AUTOSAR XML (schema 00050)
package /FCADT/ComponentTypes
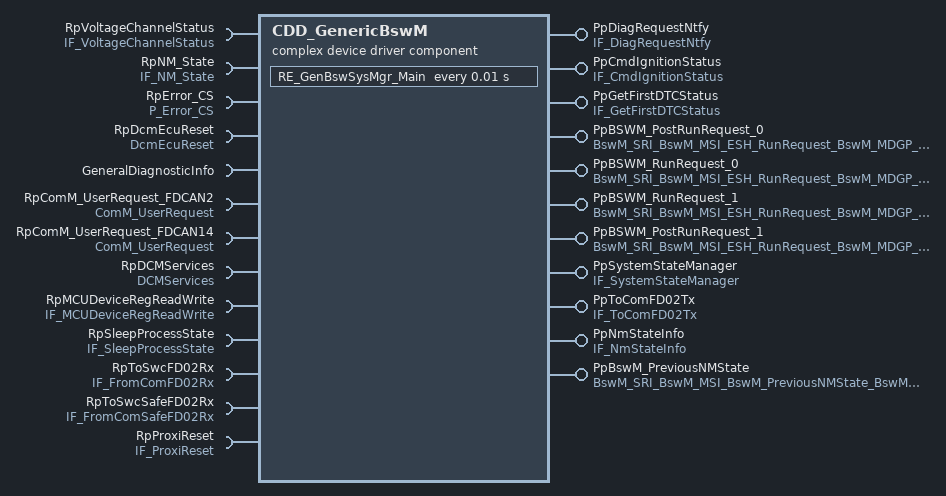
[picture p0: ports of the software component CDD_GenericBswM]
  complex device driver sw component type CDD_GenericBswM
    require port RpVoltageChannelStatus: nonqueued-receiver-com-spec{data-element=BatteryVoltageStatus, init-value=constant-reference=init_BatteryVoltageStatus}, required-interface=IF_VoltageChannelStatus
    provide port PpDiagRequestNtfy: mode-switch-sender-com-spec{mode-group=SYSModeRequestType, queue-length=1}, provided-interface=IF_DiagRequestNtfy
    require port RpNM_State: mode-switch-receiver-com-spec=Mode, required-interface=IF_NM_State
    provide port PpCmdIgnitionStatus: mode-switch-sender-com-spec{mode-group=Current_CmdIgnition, queue-length=1}, provided-interface=IF_CmdIgnitionStatus
    provide port PpGetFirstDTCStatus: nonqueued-sender-com-spec{data-element=DeFirstDTCStatus, init-value=0}, provided-interface=IF_GetFirstDTCStatus
    require port RpError_CS: client-com-spec=ReportErrorStatus1_0_QM, required-interface=P_Error_CS
    require port RpDcmEcuReset: mode-switch-receiver-com-spec=DcmEcuReset, required-interface=DcmEcuReset
    provide port PpBSWM_PostRunRequest_0: nonqueued-sender-com-spec=requestedMode, provided-interface=BswM_SRI_BswM_MSI_ESH_RunRequest_BswM_MDGP_ESH_RunRequest
    provide port PpBSWM_RunRequest_0: nonqueued-sender-com-spec=requestedMode, provided-interface=BswM_SRI_BswM_MSI_ESH_RunRequest_BswM_MDGP_ESH_RunRequest
    provide port PpBSWM_RunRequest_1: nonqueued-sender-com-spec=requestedMode, provided-interface=BswM_SRI_BswM_MSI_ESH_RunRequest_BswM_MDGP_ESH_RunRequest
    require port GeneralDiagnosticInfo: required-interface=GeneralDiagnosticInfo
      required-com-specs:
        GetMonitorStatus
        GetDebouncingOfEvent
        GetEventEnableCondition
        GetEventExtendedDataRecordEx
        GetEventFreezeFrameDataEx
        GetFaultDetectionCounter
        GetDTCOfEvent
        GetEventTested
        GetEventFailed
        GetEventStatus
        GetEventUdsStatus
    provide port PpBSWM_PostRunRequest_1: nonqueued-sender-com-spec=requestedMode, provided-interface=BswM_SRI_BswM_MSI_ESH_RunRequest_BswM_MDGP_ESH_RunRequest
    require port RpComM_UserRequest_FDCAN2: required-com-specs=[GetRequestedComMode, GetMaxComMode, GetCurrentComMode, RequestComMode], required-interface=ComM_UserRequest
    require port RpComM_UserRequest_FDCAN14: required-com-specs=[GetRequestedComMode, GetMaxComMode, GetCurrentComMode, RequestComMode], required-interface=ComM_UserRequest
    provide port PpSystemStateManager: nonqueued-sender-com-spec=SysM_State, provided-interface=IF_SystemStateManager
    5 x require port:
      RpDCMServices: required-interface=DCMServices
        required-com-specs:
          GetRequestKind
          SetActiveDiagnostic
          GetSecurityLevel
          ResetToDefaultSession
          GetSesCtrlType
          GetActiveProtocol
      RpMCUDeviceRegReadWrite: required-com-specs=[MCUWriteDeviceReg, MCUReadDeviceRegData, MCUReadDeviceReg], required-interface=IF_MCUDeviceRegReadWrite
      RpSleepProcessState: nonqueued-receiver-com-spec{data-element=status, filter=data-filter-type=ALWAYS, init-value=0}, required-interface=IF_SleepProcessState
      RpToSwcFD02Rx: required-interface=IF_FromComFD02Rx
        required-com-specs:
          data-element=Altitude_RMSE_C2, filter=data-filter-type=ALWAYS, init-value=255
          data-element=Battery_Volt_1, filter=data-filter-type=ALWAYS, init-value=0
          data-element=BSM_THA_Brk_Resp, filter=data-filter-type=ALWAYS, init-value=0
          data-element=CurrentCanNMState_FD01_BCM, filter=data-filter-type=ALWAYS, init-value=0
          data-element=CurrentCanNMState_FD01_SGW, filter=data-filter-type=ALWAYS, init-value=0
          data-element=CurrentCanNMState_FD02_BCM, filter=data-filter-type=ALWAYS, init-value=0
          data-element=CurrentCanNMState_FD02_BSM2, filter=data-filter-type=ALWAYS, init-value=0
          data-element=CurrentCanNMState_FD02_CADM2, filter=data-filter-type=ALWAYS, init-value=0
          data-element=CurrentCanNMState_FD02_EPS, filter=data-filter-type=ALWAYS, init-value=0
          data-element=CurrentCanNMState_FD02_ORC, filter=data-filter-type=ALWAYS, init-value=0
          data-element=CurrentCanNMState_FD02_SGW, filter=data-filter-type=ALWAYS, init-value=0
          data-element=CurrentCanNMState_FD02_TRLR_REV, filter=data-filter-type=ALWAYS, init-value=0
          data-element=CurrentCanNMState_FD03_BCM, filter=data-filter-type=ALWAYS, init-value=0
          data-element=CurrentCanNMState_FD03_SGW, filter=data-filter-type=ALWAYS, init-value=0
          data-element=CurrentCanNMState_FD04_BCM, filter=data-filter-type=ALWAYS, init-value=0
          data-element=CurrentCanNMState_FD08_SGW, filter=data-filter-type=ALWAYS, init-value=0
          data-element=CurrentCanNMState_FD11_SGW, filter=data-filter-type=ALWAYS, init-value=0
          data-element=CurrentFailSts_FD01_BCM, filter=data-filter-type=ALWAYS, init-value=0
          data-element=CurrentFailSts_FD01_SGW, filter=data-filter-type=ALWAYS, init-value=0
          data-element=CurrentFailSts_FD02_BCM, filter=data-filter-type=ALWAYS, init-value=0
          data-element=CurrentFailSts_FD02_BSM2, filter=data-filter-type=ALWAYS, init-value=0
          data-element=CurrentFailSts_FD02_CADM2, filter=data-filter-type=ALWAYS, init-value=0
          data-element=CurrentFailSts_FD02_EPS, filter=data-filter-type=ALWAYS, init-value=0
          data-element=CurrentFailSts_FD02_ORC, filter=data-filter-type=ALWAYS, init-value=0
          data-element=CurrentFailSts_FD02_SGW, filter=data-filter-type=ALWAYS, init-value=0
          data-element=CurrentFailSts_FD02_TRLR_REV, filter=data-filter-type=ALWAYS, init-value=0
          data-element=CurrentFailSts_FD03_BCM, filter=data-filter-type=ALWAYS, init-value=0
          data-element=CurrentFailSts_FD03_SGW, filter=data-filter-type=ALWAYS, init-value=0
          data-element=CurrentFailSts_FD04_BCM, filter=data-filter-type=ALWAYS, init-value=0
          data-element=CurrentFailSts_FD08_SGW, filter=data-filter-type=ALWAYS, init-value=0
          data-element=CurrentFailSts_FD11_SGW, filter=data-filter-type=ALWAYS, init-value=0
          data-element=DeltaTimestamp_IMUdata, filter=data-filter-type=ALWAYS, init-value=255
          data-element=DES_FD01_BCM, filter=data-filter-type=ALWAYS, init-value=0
          data-element=DES_FD01_SGW, filter=data-filter-type=ALWAYS, init-value=0
          data-element=DES_FD02_BCM, filter=data-filter-type=ALWAYS, init-value=0
          data-element=DES_FD02_BSM2, filter=data-filter-type=ALWAYS, init-value=0
          data-element=DES_FD02_CADM2, filter=data-filter-type=ALWAYS, init-value=0
          data-element=DES_FD02_EPS, filter=data-filter-type=ALWAYS, init-value=0
          data-element=DES_FD02_ORC, filter=data-filter-type=ALWAYS, init-value=0
          data-element=DES_FD02_SGW, filter=data-filter-type=ALWAYS, init-value=0
          data-element=DES_FD02_TRLR_REV, filter=data-filter-type=ALWAYS, init-value=0
          data-element=DES_FD03_BCM, filter=data-filter-type=ALWAYS, init-value=0
          data-element=DES_FD03_SGW, filter=data-filter-type=ALWAYS, init-value=0
          data-element=DES_FD04_BCM, filter=data-filter-type=ALWAYS, init-value=0
          data-element=DES_FD08_SGW, filter=data-filter-type=ALWAYS, init-value=0
          data-element=DES_FD11_SGW, filter=data-filter-type=ALWAYS, init-value=0
          data-element=Digit_{01..11}, filter=data-filter-type=ALWAYS, init-value=0
          data-element=EOL_FD01_BCM, filter=data-filter-type=ALWAYS, init-value=0
          data-element=EOL_FD01_SGW, filter=data-filter-type=ALWAYS, init-value=0
          data-element=EOL_FD02_BCM, filter=data-filter-type=ALWAYS, init-value=0
          data-element=EOL_FD02_BSM2, filter=data-filter-type=ALWAYS, init-value=0
          data-element=EOL_FD02_CADM2, filter=data-filter-type=ALWAYS, init-value=0
          data-element=EOL_FD02_EPS, filter=data-filter-type=ALWAYS, init-value=0
          data-element=EOL_FD02_ORC, filter=data-filter-type=ALWAYS, init-value=0
          data-element=EOL_FD02_SGW, filter=data-filter-type=ALWAYS, init-value=0
          data-element=EOL_FD02_TRLR_REV, filter=data-filter-type=ALWAYS, init-value=0
          data-element=EOL_FD03_BCM, filter=data-filter-type=ALWAYS, init-value=0
          data-element=EOL_FD03_SGW, filter=data-filter-type=ALWAYS, init-value=0
          data-element=EOL_FD04_BCM, filter=data-filter-type=ALWAYS, init-value=0
          data-element=EOL_FD08_SGW, filter=data-filter-type=ALWAYS, init-value=0
          data-element=EOL_FD11_SGW, filter=data-filter-type=ALWAYS, init-value=0
          data-element=EPBSts, filter=data-filter-type=ALWAYS, init-value=0
          data-element=GenericFailSts_FD01_BCM, filter=data-filter-type=ALWAYS, init-value=0
          data-element=GenericFailSts_FD01_SGW, filter=data-filter-type=ALWAYS, init-value=0
          data-element=GenericFailSts_FD02_BCM, filter=data-filter-type=ALWAYS, init-value=0
          data-element=GenericFailSts_FD02_BSM2, filter=data-filter-type=ALWAYS, init-value=0
          data-element=GenericFailSts_FD02_CADM2, filter=data-filter-type=ALWAYS, init-value=0
          data-element=GenericFailSts_FD02_EPS, filter=data-filter-type=ALWAYS, init-value=0
          data-element=GenericFailSts_FD02_ORC, filter=data-filter-type=ALWAYS, init-value=0
          data-element=GenericFailSts_FD02_SGW, filter=data-filter-type=ALWAYS, init-value=0
          data-element=GenericFailSts_FD02_TRLR_REV, filter=data-filter-type=ALWAYS, init-value=0
          data-element=GenericFailSts_FD03_BCM, filter=data-filter-type=ALWAYS, init-value=0
          data-element=GenericFailSts_FD03_SGW, filter=data-filter-type=ALWAYS, init-value=0
          data-element=GenericFailSts_FD04_BCM, filter=data-filter-type=ALWAYS, init-value=0
          data-element=GenericFailSts_FD08_SGW, filter=data-filter-type=ALWAYS, init-value=0
          data-element=GenericFailSts_FD11_SGW, filter=data-filter-type=ALWAYS, init-value=0
          data-element=Heading_Angle_C2, filter=data-filter-type=ALWAYS, init-value=65535
          data-element=IgnitionOnCounter, filter=data-filter-type=ALWAYS, init-value=0
          data-element=LatAcceleration_C2, filter=data-filter-type=ALWAYS, init-value=4095
          data-element=LatAccelerationOffset_BSM, filter=data-filter-type=ALWAYS, init-value=255
          data-element=Latitude_RMSE_C2, filter=data-filter-type=ALWAYS, init-value=255
          data-element=LHF_FastPulseCounter, filter=data-filter-type=ALWAYS, init-value=0
          data-element=LHF_Spin, filter=data-filter-type=ALWAYS, init-value=0
          data-element=LHFWheelSpeed, filter=data-filter-type=ALWAYS, init-value=0
          data-element=LHR_FastPulseCounter, filter=data-filter-type=ALWAYS, init-value=0
          data-element=LHR_Spin, filter=data-filter-type=ALWAYS, init-value=0
          data-element=LHRWheelSpeed, filter=data-filter-type=ALWAYS, init-value=0
          data-element=LongAcceleration_C2, filter=data-filter-type=ALWAYS, init-value=4095
          data-element=LongAccelerationOffset_BSM, filter=data-filter-type=ALWAYS, init-value=255
          data-element=Longitude_RMSE_C2, filter=data-filter-type=ALWAYS, init-value=255
          data-element=OperationalModeSts, filter=data-filter-type=ALWAYS, init-value=0
          data-element=Pitch_RMSE_C2, filter=data-filter-type=ALWAYS, init-value=255
          data-element=PitchRate_C2, filter=data-filter-type=ALWAYS, init-value=4095
          data-element=PreviousCanNMState_FD01_BCM, filter=data-filter-type=ALWAYS, init-value=0
          data-element=PreviousCanNMState_FD01_SGW, filter=data-filter-type=ALWAYS, init-value=0
          data-element=PreviousCanNMState_FD02_BCM, filter=data-filter-type=ALWAYS, init-value=0
          data-element=PreviousCanNMState_FD02_BSM2, filter=data-filter-type=ALWAYS, init-value=0
          data-element=PreviousCanNMState_FD02_CADM2, filter=data-filter-type=ALWAYS, init-value=0
          data-element=PreviousCanNMState_FD02_EPS, filter=data-filter-type=ALWAYS, init-value=0
          data-element=PreviousCanNMState_FD02_ORC, filter=data-filter-type=ALWAYS, init-value=0
          data-element=PreviousCanNMState_FD02_SGW, filter=data-filter-type=ALWAYS, init-value=0
          data-element=PreviousCanNMState_FD02_TRLR_REV, filter=data-filter-type=ALWAYS, init-value=0
          data-element=PreviousCanNMState_FD03_BCM, filter=data-filter-type=ALWAYS, init-value=0
          data-element=PreviousCanNMState_FD03_SGW, filter=data-filter-type=ALWAYS, init-value=0
          data-element=PreviousCanNMState_FD04_BCM, filter=data-filter-type=ALWAYS, init-value=0
          data-element=PreviousCanNMState_FD08_SGW, filter=data-filter-type=ALWAYS, init-value=0
          data-element=PreviousCanNMState_FD11_SGW, filter=data-filter-type=ALWAYS, init-value=0
          data-element=REF_VEH_SPEED, filter=data-filter-type=ALWAYS, init-value=1023
          data-element=RemStActvSts, filter=data-filter-type=ALWAYS, init-value=0
          data-element=RHF_FastPulseCounter, filter=data-filter-type=ALWAYS, init-value=0
          data-element=RHF_Spin, filter=data-filter-type=ALWAYS, init-value=0
          data-element=RHFWheelSpeed, filter=data-filter-type=ALWAYS, init-value=0
          data-element=RHR_FastPulseCounter, filter=data-filter-type=ALWAYS, init-value=0
          data-element=RHR_Spin, filter=data-filter-type=ALWAYS, init-value=0
          data-element=RHRWheelSpeed, filter=data-filter-type=ALWAYS, init-value=0
          data-element=Roll_RMSE_C2, filter=data-filter-type=ALWAYS, init-value=255
          data-element=RollRate_C2, filter=data-filter-type=ALWAYS, init-value=4095
          data-element=SBR1RowDriverSeatSts, filter=data-filter-type=ALWAYS, init-value=3
          data-element=StayActiveSource_FD01_BCM, filter=data-filter-type=ALWAYS, init-value=0
          data-element=StayActiveSource_FD01_SGW, filter=data-filter-type=ALWAYS, init-value=0
          data-element=StayActiveSource_FD02_BCM, filter=data-filter-type=ALWAYS, init-value=0
          data-element=StayActiveSource_FD02_BSM2, filter=data-filter-type=ALWAYS, init-value=0
          data-element=StayActiveSource_FD02_CADM2, filter=data-filter-type=ALWAYS, init-value=0
          data-element=StayActiveSource_FD02_EPS, filter=data-filter-type=ALWAYS, init-value=0
          data-element=StayActiveSource_FD02_ORC, filter=data-filter-type=ALWAYS, init-value=0
          data-element=StayActiveSource_FD02_SGW, filter=data-filter-type=ALWAYS, init-value=0
          data-element=StayActiveSource_FD02_TRLR_REV, filter=data-filter-type=ALWAYS, init-value=0
          data-element=StayActiveSource_FD03_BCM, filter=data-filter-type=ALWAYS, init-value=0
          data-element=StayActiveSource_FD03_SGW, filter=data-filter-type=ALWAYS, init-value=0
          data-element=StayActiveSource_FD04_BCM, filter=data-filter-type=ALWAYS, init-value=0
          data-element=StayActiveSource_FD08_SGW, filter=data-filter-type=ALWAYS, init-value=0
          data-element=StayActiveSource_FD11_SGW, filter=data-filter-type=ALWAYS, init-value=0
          data-element=TotalOdometer, filter=data-filter-type=ALWAYS, init-value=0
          data-element=TRSC_CenterBtn_Sts, filter=data-filter-type=ALWAYS, init-value=0
          data-element=TRSC_EnableBtn_Sts, filter=data-filter-type=ALWAYS, init-value=0
          data-element=TRSC_RawKnob, filter=data-filter-type=ALWAYS, init-value=0
          data-element=TurnIndicatorSts, filter=data-filter-type=ALWAYS, init-value=0
          data-element=VehicleStandStillSts, filter=data-filter-type=ALWAYS, init-value=1
          data-element=VerticalAcceleration_C2, filter=data-filter-type=ALWAYS, init-value=4095
          data-element=WakeupSource_FD01_ADCM, filter=data-filter-type=ALWAYS, init-value=0
          data-element=WakeupSource_FD01_BCM, filter=data-filter-type=ALWAYS, init-value=0
          data-element=WakeupSource_FD01_SGW, filter=data-filter-type=ALWAYS, init-value=0
          data-element=WakeupSource_FD02_BCM, filter=data-filter-type=ALWAYS, init-value=0
          data-element=WakeupSource_FD02_BSM2, filter=data-filter-type=ALWAYS, init-value=0
          data-element=WakeupSource_FD02_CADM2, filter=data-filter-type=ALWAYS, init-value=0
          data-element=WakeupSource_FD02_EPS, filter=data-filter-type=ALWAYS, init-value=0
          data-element=WakeupSource_FD02_ORC, filter=data-filter-type=ALWAYS, init-value=0
          data-element=WakeupSource_FD02_SGW, filter=data-filter-type=ALWAYS, init-value=0
          data-element=WakeupSource_FD02_TRLR_REV, filter=data-filter-type=ALWAYS, init-value=0
          data-element=WakeupSource_FD03_BCM, filter=data-filter-type=ALWAYS, init-value=0
          data-element=WakeupSource_FD03_SGW, filter=data-filter-type=ALWAYS, init-value=0
          data-element=WakeupSource_FD04_BCM, filter=data-filter-type=ALWAYS, init-value=0
          data-element=WakeupSource_FD08_SGW, filter=data-filter-type=ALWAYS, init-value=0
          data-element=WakeupSource_FD11_SGW, filter=data-filter-type=ALWAYS, init-value=0
          data-element=YawRate_C2, filter=data-filter-type=ALWAYS, init-value=4095
          data-element=YawRate_RMSE_C2, filter=data-filter-type=ALWAYS, init-value=255
      RpToSwcSafeFD02Rx: required-interface=IF_FromComSafeFD02Rx
        required-com-specs:
          data-element=Active_Park_Mode, filter=data-filter-type=ALWAYS, init-value=0
          data-element=Active_Park_Prox_Chime, filter=data-filter-type=ALWAYS, init-value=0
          data-element=APARequestSts, filter=data-filter-type=ALWAYS, init-value=0
          data-element=Backup_Cam_Delay, filter=data-filter-type=ALWAYS, init-value=0
          data-element=Brk_Stat, filter=data-filter-type=ALWAYS, init-value=0
          data-element=CmdIgnSts, filter=data-filter-type=ALWAYS, init-value=0
          data-element=DriverDoorSts, filter=data-filter-type=ALWAYS, init-value=0
          data-element=DynamicGrid, filter=data-filter-type=ALWAYS, init-value=1
          data-element=ExternalTemperature, filter=data-filter-type=ALWAYS, init-value=0
          data-element=FT_PAMRequestSts, filter=data-filter-type=ALWAYS, init-value=0
          data-element=Fwrd_Cam_Guidelines, filter=data-filter-type=ALWAYS, init-value=0
          data-element=GearEngaged, filter=data-filter-type=ALWAYS, init-value=0
          data-element=HAS_Status_C2, filter=data-filter-type=ALWAYS, init-value=0
          data-element=LanguageSelection, filter=data-filter-type=ALWAYS, init-value=0
          data-element=LatAcceleration_BSM, filter=data-filter-type=ALWAYS, init-value=4095
          data-element=LHRDoorSts, filter=data-filter-type=ALWAYS, init-value=0
          data-element=LongAcceleration_BSM, filter=data-filter-type=ALWAYS, init-value=4095
          data-element=LwsAngle, filter=data-filter-type=ALWAYS, init-value=0
          data-element=LwsAngleType, filter=data-filter-type=ALWAYS, init-value=0
          data-element=LwsSpeed, filter=data-filter-type=ALWAYS, init-value=0
          data-element=MRM_STATUS_C2, filter=data-filter-type=ALWAYS, init-value=0
          data-element=PamChimeVolumeFront, filter=data-filter-type=ALWAYS, init-value=1
          data-element=PamChimeVolumeRear, filter=data-filter-type=ALWAYS, init-value=1
          data-element=PAMRequestSts, filter=data-filter-type=ALWAYS, init-value=0
          data-element=PsngrDoorSts, filter=data-filter-type=ALWAYS, init-value=0
          data-element=Rear_Brk_Asst, filter=data-filter-type=ALWAYS, init-value=0
          data-element=RHatchSts, filter=data-filter-type=ALWAYS, init-value=0
          data-element=RHRDoorSts, filter=data-filter-type=ALWAYS, init-value=0
          data-element=ShiftLeverPosition, filter=data-filter-type=ALWAYS, init-value=0
          data-element=SVC_Guidelines, filter=data-filter-type=ALWAYS, init-value=0
          data-element=TargetGear, filter=data-filter-type=ALWAYS, init-value=15
          data-element=TCASERANGESTATUS, filter=data-filter-type=ALWAYS, init-value=0
          data-element=TGW_CAMERA_DISP_STAT, filter=data-filter-type=ALWAYS, init-value=0
          data-element=TrailerConnectionSts, filter=data-filter-type=ALWAYS, init-value=0
          data-element=TRANS_ADAS_Inhibit, filter=data-filter-type=ALWAYS, init-value=0
          data-element=TransmissionSailingSts, filter=data-filter-type=ALWAYS, init-value=0
          data-element=VehicleSpeedVSOSig, filter=data-filter-type=ALWAYS, init-value=0
          data-element=YawRate_BSM, filter=data-filter-type=ALWAYS, init-value=4095
          data-element=VIN_MSG, filter=data-filter-type=ALWAYS
          data-element=VIN_DATA, filter=data-filter-type=ALWAYS
          data-element=RR_Lvl_Adj, filter=data-filter-type=ALWAYS
          data-element=RR_Lvl, filter=data-filter-type=ALWAYS
          data-element=RL_Lvl_Adj, filter=data-filter-type=ALWAYS
          data-element=RL_Lvl, filter=data-filter-type=ALWAYS
          data-element=HU_TRSC_EnableBtn_Sts, filter=data-filter-type=ALWAYS
          data-element=GearEngagedForDisplay, filter=data-filter-type=ALWAYS
          data-element=FR_Lvl_Adj, filter=data-filter-type=ALWAYS
          data-element=FR_Lvl, filter=data-filter-type=ALWAYS
          data-element=FL_Lvl_Adj, filter=data-filter-type=ALWAYS
          data-element=FL_Lvl, filter=data-filter-type=ALWAYS
          data-element=ESS_ENG_ST_W, filter=data-filter-type=ALWAYS
          data-element=EngineSts_W, filter=data-filter-type=ALWAYS
          data-element=ECM_TRSC_Resp, filter=data-filter-type=ALWAYS
          data-element=ECM_THA_Resp, filter=data-filter-type=ALWAYS
          data-element=ASCM_SysFail, filter=data-filter-type=ALWAYS
          data-element=ASCM_Stat, filter=data-filter-type=ALWAYS
          data-element=PdlPosActual, filter=data-filter-type=ALWAYS
          data-element=THA_SteeringTouchStat, filter=data-filter-type=ALWAYS
          data-element=EPS_THA_SteeringTorqueResp, filter=data-filter-type=ALWAYS
          data-element=EPS_THA_DriverTorqueOverride, filter=data-filter-type=ALWAYS
          data-element=EPS_SteeringTouq_Resp, filter=data-filter-type=ALWAYS
          data-element=EPS_SteeringTouchStat, filter=data-filter-type=ALWAYS
          data-element=ShiftLeverPositionReq, filter=data-filter-type=ALWAYS
          data-element=Shifter_ADAS_Inhibit, filter=data-filter-type=ALWAYS
          data-element=ITBM_TrlrStat, filter=data-filter-type=ALWAYS
          data-element=CM_TCH_Y_COORD, filter=data-filter-type=ALWAYS
          data-element=CM_TCH_X_COORD, filter=data-filter-type=ALWAYS
          data-element=CM_TCH_STAT, filter=data-filter-type=ALWAYS
          data-element=CameraDisplaySts2, filter=data-filter-type=ALWAYS
    provide port PpToComFD02Tx: provided-interface=IF_ToComFD02Tx
      provided-com-specs:
        data-element=CurrentCanNMState_FD02_PAM, init-value=0
        data-element=CurrentFailSts_FD02_PAM, init-value=0
        data-element=DES_FD02_PAM, init-value=0
        data-element=Digit_{01..11}_PAM, init-value=0
        data-element=EOL_FD02_PAM, init-value=0
        data-element=GenericFailSts_FD02_PAM, init-value=0
        {data-element=N_PDU, init-value=[rule-based-values={rule=FILL_UNTIL_END, rule-arguments=0}]}
        data-element=PreviousCanNMState_FD02_PAM, init-value=0
        {data-element=StayActiveSource_FD02_PAM, init-value=[rule-based-values={rule=FILL_UNTIL_END, rule-arguments=0}]}
        data-element=THA_EPB_Req, init-value=0
        data-element=THA_Speed_Limit, init-value=0
        data-element=THA_SpeedLimit_Req, init-value=0
        data-element=THA_STAT, init-value=0
        data-element=THA_SteeringDamping, init-value=78.125
        data-element=THA_SteeringTorqueInfo, init-value=0
        data-element=THA_SteeringTorqueReq, init-value=0
        data-element=Trailer_Angle, init-value=0
        data-element=Trailer_Angle_Sign, init-value=0
        data-element=Trailer_Calibration, init-value=0
        data-element=TrlrHitchLight_Cntrl, init-value=0
        data-element=TRSC_PopupDisp_Info, init-value=0
        data-element=TRSC_SpeedLimit_Req, init-value=0
        data-element=TRSC_STAT, init-value=1
        data-element=TRSC_SteeringDamping, init-value=100
        data-element=TRSC_SteeringTorqueInfo, init-value=0
        data-element=TRSC_SteeringTorqueReq, init-value=0
        data-element=TRSC_VehicleStop_Req, init-value=3
        data-element=TRSCMoreCamRQSts, init-value=0
        data-element=WakeupSource_FD02_PAM, init-value=0
        data-element=TRSC_PopupDisp_Info2, init-value=0
    require port RpProxiReset: nonqueued-receiver-com-spec{data-element=ProxiDataflag_b, filter=data-filter-type=ALWAYS, init-value=0}, required-interface=IF_ProxiReset
    provide port PpNmStateInfo: nonqueued-sender-com-spec{data-element=v_IsNmStateNormal_b, init-value=0}, provided-interface=IF_NmStateInfo
    provide port PpBswM_PreviousNMState: nonqueued-sender-com-spec{data-element=requestedMode, init-value=0}, provided-interface=BswM_SRI_BswM_MSI_BswM_PreviousNMState_BswM_MDGP_BswM_PreviousNMState
    behavior CDD_GenericBswM_InternalBehavior: data-type-mapping=DataTypeMappings_DEV, handle-termination-and-restart=NO-SUPPORT, port-api-option{enable-take-address=false, error-handling=NO-TRANSFORMER-ERROR-HANDLING, indirect-api=false, port=RpVoltageChannelStatus}
      init event InitEvent: start-on-event=RE_GenBswSysMgr_Init
      timing event TMT_RE_GenBswSysMgr_Main: start-on-event=RE_GenBswSysMgr_Main, period=0.01
      8 x swc mode switch event:
        MST_RE_GenericBswM_HARDResetReq_0: start-on-event=RE_GenericBswM_HARDResetReq, activation=ON-TRANSITION, mode=[RpDcmEcuReset.DcmEcuReset.HARD, RpDcmEcuReset.DcmEcuReset.EXECUTE]
        MST_RE_GenericBswM_JumpToBootReq_0: start-on-event=RE_GenericBswM_JumpToBootReq, activation=ON-TRANSITION, mode=[RpDcmEcuReset.DcmEcuReset.JUMPTOBOOTLOADER, RpDcmEcuReset.DcmEcuReset.EXECUTE]
        MST_RE_UpdateNMState_0: activation-reason-representation=ActReason_BUSSLEEP, start-on-event=RE_UpdateNMState, activation=ON-ENTRY, mode=RpNM_State.Mode.NM_STATE_BUS_SLEEP
        MST_RE_UpdateNMState_1: activation-reason-representation=ActReason_NORMAL, start-on-event=RE_UpdateNMState, activation=ON-ENTRY, mode=RpNM_State.Mode.NM_STATE_NORMAL
        MST_RE_UpdateNMState_2: activation-reason-representation=ActReason_PREPARESLEEP, start-on-event=RE_UpdateNMState, activation=ON-ENTRY, mode=RpNM_State.Mode.NM_STATE_PREPARE_SLEEP
        MST_RE_UpdateNMState_3: activation-reason-representation=ActReason_READYSLEEP, start-on-event=RE_UpdateNMState, activation=ON-ENTRY, mode=RpNM_State.Mode.NM_STATE_READY_SLEEP
        MST_RE_UpdateNMState_4: activation-reason-representation=ActReason_REPEATMSG, start-on-event=RE_UpdateNMState, activation=ON-ENTRY, mode=RpNM_State.Mode.NM_STATE_REPEAT
        MST_RE_UpdateNMState_5: activation-reason-representation=ActReason_UNINIT, start-on-event=RE_UpdateNMState, activation=ON-ENTRY, mode=RpNM_State.Mode.NM_UINIT
      explicit-inter-runnable-variables:
        data Irv_ChangeSYSStateReq: type=ChangeSYSState_t, init-value=0
        data Irv_PreviousNMState: type=uint16, init-value=0
      5 x runnable:
        RE_GenBswSysMgr_Init
          read-local-variables:
            access Read_Irv_ChangeSYSStateReq: accessed-variable=Irv_ChangeSYSStateReq
            access Read_Irv_PreviousNMState: accessed-variable=Irv_PreviousNMState
          written-local-variables:
            access WRITE_Irv_ChangeSYSStateReq: accessed-variable=Irv_ChangeSYSStateReq
            access WRITE_Irv_PreviousNMState: accessed-variable=Irv_PreviousNMState
        RE_GenBswSysMgr_Main: mode-access-point=RpNM_State.Mode
          data-receive-point-by-arguments:
            5 x access:
              REC_RpVoltageChannelStatus_BatteryVoltageStatus: accessed-variable=RpVoltageChannelStatus.BatteryVoltageStatus
              REC_RpSleepProcessState_status: accessed-variable=RpSleepProcessState.status
              REC_RpToSwcSafeFD02Rx_CmdIgnSts: accessed-variable=RpToSwcSafeFD02Rx.CmdIgnSts
              REC_RpToSwcFD02Rx_TotalOdometer: accessed-variable=RpToSwcFD02Rx.TotalOdometer
              REC_RpProxiReset_ProxiDataflag_b: accessed-variable=RpProxiReset.ProxiDataflag_b
          data-send-points:
            15 x access:
              SEND_PpBSWM_PostRunRequest_0_requestedMode: accessed-variable=PpBSWM_PostRunRequest_0.requestedMode
              SEND_PpBSWM_RunRequest_0_requestedMode: accessed-variable=PpBSWM_RunRequest_0.requestedMode
              SEND_PpBSWM_RunRequest_1_requestedMode: accessed-variable=PpBSWM_RunRequest_1.requestedMode
              SEND_PpBSWM_PostRunRequest_1_requestedMode: accessed-variable=PpBSWM_PostRunRequest_1.requestedMode
              SEND_PpGetFirstDTCStatus_DeFirstDTCStatus: accessed-variable=PpGetFirstDTCStatus.DeFirstDTCStatus
              SEND_PpSystemStateManager_SysM_State: accessed-variable=PpSystemStateManager.SysM_State
              SEND_PpToComFD02Tx_CurrentCanNMState_FD02_PAM: accessed-variable=PpToComFD02Tx.CurrentCanNMState_FD02_PAM
              SEND_PpToComFD02Tx_CurrentFailSts_FD02_PAM: accessed-variable=PpToComFD02Tx.CurrentFailSts_FD02_PAM
              SEND_PpToComFD02Tx_DES_FD02_PAM: accessed-variable=PpToComFD02Tx.DES_FD02_PAM
              SEND_PpToComFD02Tx_GenericFailSts_FD02_PAM: accessed-variable=PpToComFD02Tx.GenericFailSts_FD02_PAM
              SEND_PpToComFD02Tx_PreviousCanNMState_FD02_PAM: accessed-variable=PpToComFD02Tx.PreviousCanNMState_FD02_PAM
              SEND_PpToComFD02Tx_StayActiveSource_FD02_PAM: accessed-variable=PpToComFD02Tx.StayActiveSource_FD02_PAM
              SEND_PpToComFD02Tx_WakeupSource_FD02_PAM: accessed-variable=PpToComFD02Tx.WakeupSource_FD02_PAM
              SEND_PpNmStateInfo_v_IsNmStateNormal_b: accessed-variable=PpNmStateInfo.v_IsNmStateNormal_b
              SEND_PpBswM_PreviousNMState_requestedMode: accessed-variable=PpBswM_PreviousNMState.requestedMode
          mode switch point SWITCH_PpDiagRequestNtfy_SYSModeRequestType: mode-group=PpDiagRequestNtfy.SYSModeRequestType
          read-local-variables:
            access Read_Irv_ChangeSYSStateReq: accessed-variable=Irv_ChangeSYSStateReq
            access Read_Irv_PreviousNMState: accessed-variable=Irv_PreviousNMState
          8 x sync call:
            SC_GeneralDiagnosticInfo_GetEventUdsStatus: operation=GeneralDiagnosticInfo.GetEventUdsStatus
            SC_RpError_CS_ReportErrorStatus1_0_QM: operation=RpError_CS.ReportErrorStatus1_0_QM
            SC_RpComM_UserRequest_FDCAN14_RequestComMode: operation=RpComM_UserRequest_FDCAN14.RequestComMode
            SC_RpComM_UserRequest_FDCAN2_RequestComMode: operation=RpComM_UserRequest_FDCAN2.RequestComMode
            SC_RpDCMServices_GetSesCtrlType: operation=RpDCMServices.GetSesCtrlType
            SC_RpMCUDeviceRegReadWrite_MCUReadDeviceReg: operation=RpMCUDeviceRegReadWrite.MCUReadDeviceReg
            SC_RpMCUDeviceRegReadWrite_MCUReadDeviceRegData: operation=RpMCUDeviceRegReadWrite.MCUReadDeviceRegData
            SC_RpMCUDeviceRegReadWrite_MCUWriteDeviceReg: operation=RpMCUDeviceRegReadWrite.MCUWriteDeviceReg
          written-local-variables:
            access WRITE_Irv_ChangeSYSStateReq: accessed-variable=Irv_ChangeSYSStateReq
            access WRITE_Irv_PreviousNMState: accessed-variable=Irv_PreviousNMState
        RE_GenericBswM_HARDResetReq
          read-local-variables:
            access Read_Irv_ChangeSYSStateReq: accessed-variable=Irv_ChangeSYSStateReq
            access Read_Irv_PreviousNMState: accessed-variable=Irv_PreviousNMState
          written-local-variables:
            access WRITE_Irv_ChangeSYSStateReq: accessed-variable=Irv_ChangeSYSStateReq
            access WRITE_Irv_PreviousNMState: accessed-variable=Irv_PreviousNMState
        RE_GenericBswM_JumpToBootReq
          read-local-variables:
            access Read_Irv_ChangeSYSStateReq: accessed-variable=Irv_ChangeSYSStateReq
            access Read_Irv_PreviousNMState: accessed-variable=Irv_PreviousNMState
          written-local-variables:
            access WRITE_Irv_ChangeSYSStateReq: accessed-variable=Irv_ChangeSYSStateReq
            access WRITE_Irv_PreviousNMState: accessed-variable=Irv_PreviousNMState
        RE_UpdateNMState
          6 x executable entity activation reason:
            ActReason_UNINIT: bit-position=0
            ActReason_BUSSLEEP: bit-position=1
            ActReason_PREPARESLEEP: bit-position=2
            ActReason_READYSLEEP: bit-position=3
            ActReason_NORMAL: bit-position=4
            ActReason_REPEATMSG: bit-position=5
          read-local-variables:
            access Read_Irv_ChangeSYSStateReq: accessed-variable=Irv_ChangeSYSStateReq
            access Read_Irv_PreviousNMState: accessed-variable=Irv_PreviousNMState
          written-local-variables:
            access WRITE_Irv_ChangeSYSStateReq: accessed-variable=Irv_ChangeSYSStateReq
            access WRITE_Irv_PreviousNMState: accessed-variable=Irv_PreviousNMState
  swc implementation CDD_GenericBswM_Implementation: programming-language=C, vendor-id=0, behavior=CDD_GenericBswM_InternalBehavior
    code-descriptors:
      code Default: artifact-descriptors=autosar-engineering-object=category=SWSRC
